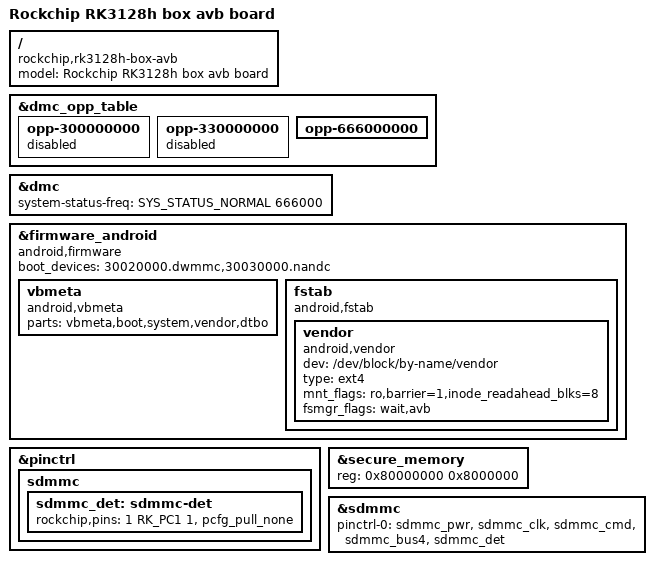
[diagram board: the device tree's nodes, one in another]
// SPDX-License-Identifier: (GPL-2.0+ OR MIT)
/*
 * Copyright (c) 2018 Fuzhou Rockchip Electronics Co., Ltd
 */

/dts-v1/;

#include "rk3128h-box.dtsi"

/ {
	model = "Rockchip RK3128h box avb board";
	compatible = "rockchip,rk3128h-box-avb", "rockchip,rk3128h";
};

&dmc_opp_table {
	opp-300000000 {
		status = "disabled";
	};
	opp-330000000 {
		status = "disabled";
	};
	opp-666000000 {
		status = "okay";
	};
};

&dmc {
	system-status-freq = <
		/*system status freq(KHz)*/
		SYS_STATUS_NORMAL	666000
	>;
};

&firmware_android {
	compatible = "android,firmware";
	boot_devices = "30020000.dwmmc,30030000.nandc";
	vbmeta {
		compatible = "android,vbmeta";
		parts = "vbmeta,boot,system,vendor,dtbo";
	};
	fstab {
		compatible = "android,fstab";
		vendor {
			compatible = "android,vendor";
			dev = "/dev/block/by-name/vendor";
			type = "ext4";
			mnt_flags = "ro,barrier=1,inode_readahead_blks=8";
			fsmgr_flags = "wait,avb";
		};
	};
};

&pinctrl {
	sdmmc {
		sdmmc_det: sdmmc-det {
			rockchip,pins = <1 RK_PC1 1 &pcfg_pull_none>;
		};
	};
};

&secure_memory {
	/*
	 * enable like this:
	 * reg = <0x80000000 0x10000000>;
	 */
	reg = <0x80000000 0x8000000>;
};

&sdmmc {
	pinctrl-0 = <&sdmmc_pwr &sdmmc_clk &sdmmc_cmd &sdmmc_bus4 &sdmmc_det>;
};
